VERSION ""

NS_ :

BS_:

BU_: Vector__XXX

// Jaguar XF X250 — MS Bus (125 kbps)
// Confidence prefixes: c_ confirmed, i_ inferred, u_ unknown
// See README.md for sourcing and confidence definitions.
// Do not apply PSA or other-platform DBC labels to these frame IDs.

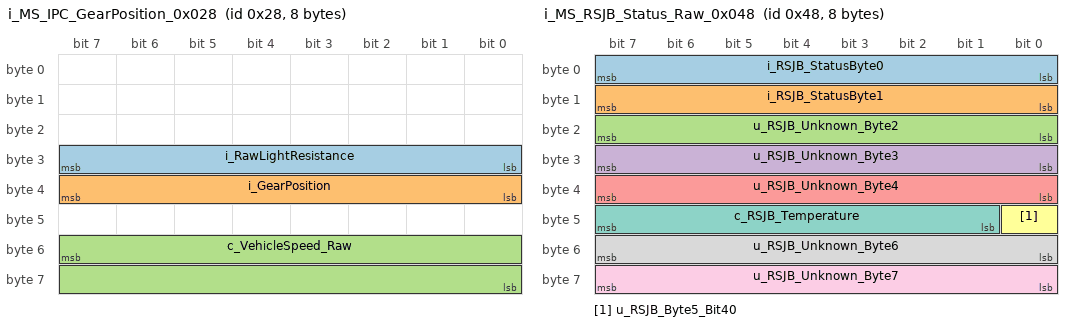
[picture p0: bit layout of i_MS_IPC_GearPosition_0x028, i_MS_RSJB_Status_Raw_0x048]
BO_ 40 i_MS_IPC_GearPosition_0x028: 8 Vector__XXX
 SG_ i_RawLightResistance : 24|8@1+ (1,0) [0|255] "" Vector__XXX
 SG_ i_GearPosition : 32|8@1+ (1,0) [0|255] "" Vector__XXX
 SG_ c_VehicleSpeed_Raw : 55|16@0+ (1,0) [0|65535] "raw" Vector__XXX

BO_ 72 i_MS_RSJB_Status_Raw_0x048: 8 Vector__XXX
 SG_ i_RSJB_StatusByte0 : 0|8@1+ (1,0) [0|255] "" Vector__XXX
 SG_ i_RSJB_StatusByte1 : 8|8@1+ (1,0) [0|255] "" Vector__XXX
 SG_ u_RSJB_Unknown_Byte2 : 16|8@1+ (1,0) [0|255] "" Vector__XXX
 SG_ u_RSJB_Unknown_Byte3 : 24|8@1+ (1,0) [0|255] "" Vector__XXX
 SG_ u_RSJB_Unknown_Byte4 : 32|8@1+ (1,0) [0|255] "" Vector__XXX
 SG_ u_RSJB_Byte5_Bit40 : 40|1@1+ (1,0) [0|1] "" Vector__XXX
 SG_ c_RSJB_Temperature : 41|7@1+ (1,-40) [-40|80] "degC" Vector__XXX
 SG_ u_RSJB_Unknown_Byte6 : 48|8@1+ (1,0) [0|255] "" Vector__XXX
 SG_ u_RSJB_Unknown_Byte7 : 56|8@1+ (1,0) [0|255] "" Vector__XXX

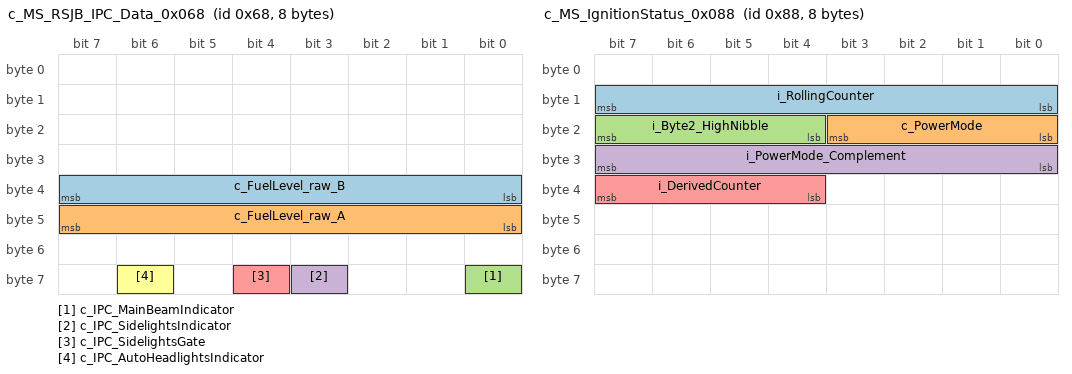
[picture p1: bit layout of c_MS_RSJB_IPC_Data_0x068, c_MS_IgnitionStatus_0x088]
BO_ 104 c_MS_RSJB_IPC_Data_0x068: 8 Vector__XXX
 SG_ c_FuelLevel_raw_B             : 32|8@1+ (1,0) [0|65535] "" Vector__XXX
 SG_ c_FuelLevel_raw_A             : 40|8@1+ (1,0) [0|65535] "" Vector__XXX
 SG_ c_IPC_MainBeamIndicator       : 56|1@1+  (1,0) [0|1] "" Vector__XXX
 SG_ c_IPC_SidelightsIndicator     : 59|1@1+  (1,0) [0|1] "" Vector__XXX
 SG_ c_IPC_SidelightsGate          : 60|1@1+  (1,0) [0|1] "" Vector__XXX
 SG_ c_IPC_AutoHeadlightsIndicator : 62|1@1+ (1,0) [0|1] "" Vector__XXX

BO_ 136 c_MS_IgnitionStatus_0x088: 8 Vector__XXX
 SG_ i_RollingCounter : 8|8@1+ (1,0) [0|255] "" Vector__XXX
 SG_ c_PowerMode : 16|4@1+ (1,0) [0|15] "" Vector__XXX
 SG_ i_Byte2_HighNibble : 20|4@1+ (1,0) [0|15] "" Vector__XXX
 SG_ i_PowerMode_Complement : 24|8@1+ (1,0) [0|255] "" Vector__XXX
 SG_ i_DerivedCounter : 36|4@1+ (1,0) [0|15] "" Vector__XXX

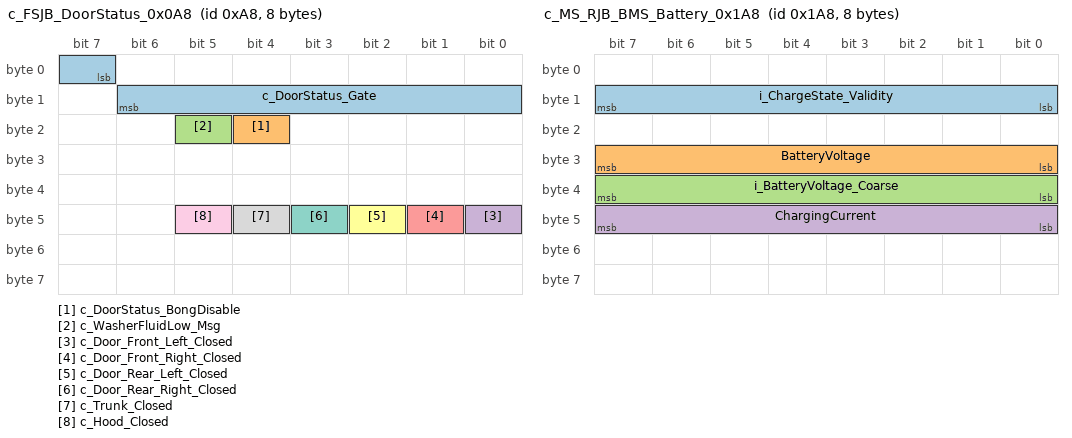
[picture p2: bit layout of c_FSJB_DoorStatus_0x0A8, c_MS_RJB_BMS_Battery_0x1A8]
BO_ 168 c_FSJB_DoorStatus_0x0A8: 8 Vector__XXX
 SG_ c_DoorStatus_Gate           : 7|8@1+ (1,0) [0|1] "" Vector__XXX
 SG_ c_DoorStatus_BongDisable    : 20|1@1+ (1,0) [0|1] "" Vector__XXX
 SG_ c_WasherFluidLow_Msg        : 21|1@1+ (1,0) [0|1] "" Vector__XXX
 SG_ c_Door_Front_Left_Closed    : 40|1@1+ (1,0) [0|1] "" Vector__XXX
 SG_ c_Door_Front_Right_Closed   : 41|1@1+ (1,0) [0|1] "" Vector__XXX
 SG_ c_Door_Rear_Left_Closed     : 42|1@1+ (1,0) [0|1] "" Vector__XXX
 SG_ c_Door_Rear_Right_Closed    : 43|1@1+ (1,0) [0|1] "" Vector__XXX
 SG_ c_Trunk_Closed              : 44|1@1+ (1,0) [0|1] "" Vector__XXX
 SG_ c_Hood_Closed               : 45|1@1+ (1,0) [0|1] "" Vector__XXX

BO_ 200 c_MS_IPC_Unknown_0x0C8: 8 Vector__XXX
BO_ 264 c_MS_IPC_Unknown_0x108: 8 Vector__XXX
 SG_ c_RPM       : 20|13@0+ (1,0) [0|8191] "rpm" Vector__XXX
BO_ 360 c_MS_IPC_TurnIndicatorRequest_0x168: 8 Vector__XXX
 SG_ c_TurnSwitchState : 0|4@1+ (1,0) [0|15] "" Vector__XXX

BO_ 392 c_MS_IPC_Odometer_0x188: 8 Vector__XXX
 SG_ c_Odometer_KM_Raw   : 32|24@1+  (1,0) [0|16777215] "" Vector__XXX
 SG_ i_AliveToggle_b0    : 6|1@1+ (1,0) [0|1] "" Vector__XXX

BO_ 424 c_MS_RJB_BMS_Battery_0x1A8: 8 Vector__XXX
 SG_ i_ChargeState_Validity : 8|8@1+ (1,0) [0|255] "" Vector__XXX
 SG_ BatteryVoltage : 24|8@1+ (0.050000000745,6) [6|18.75] "V" Vector__XXX
 SG_ i_BatteryVoltage_Coarse : 32|8@1+ (0.1658,7.71) [8|50] "V" Vector__XXX
 SG_ ChargingCurrent : 40|8@1+ (1,-127) [-127|128] "A" Vector__XXX

BO_ 456 i_Smart_Key_LateMY_Unknown_0x1C8: 8 Vector__XXX
 SG_ c_IPC_SmartKeyBatteryLow_Gate   : 3|1@1+  (1,0) [0|1] "" Vector__XXX
 SG_ c_IPC_SmartKeyBatteryLow_Msg    : 39|1@1+  (1,0) [0|1] "" Vector__XXX

BO_ 472 c_MS_IPC_ClockCounterMirror_0x1D8: 8 Vector__XXX
 SG_ c_ClockCounter_32 : 39|32@0+ (1,0) [0|4294967295] "count" Vector__XXX
BO_ 488 c_LateMY_Unknown_0x1E8: 8 Vector__XXX

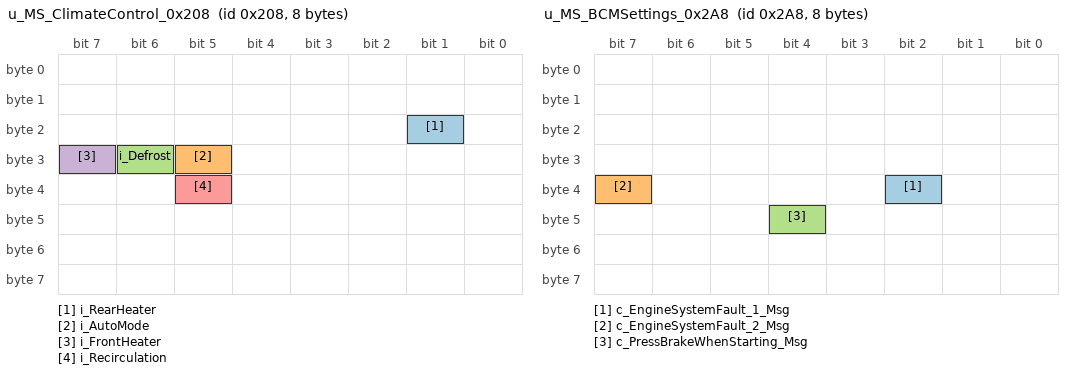
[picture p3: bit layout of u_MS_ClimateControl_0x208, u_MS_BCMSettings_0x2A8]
BO_ 520 u_MS_ClimateControl_0x208: 8 Vector__XXX
 SG_ i_RearHeater : 17|1@1+ (1,0) [0|1] "" Vector__XXX
 SG_ i_AutoMode : 29|1@1+ (1,0) [0|1] "" Vector__XXX
 SG_ i_Defrost : 30|1@1+ (1,0) [0|1] "" Vector__XXX
 SG_ i_FrontHeater : 31|1@1+ (1,0) [0|1] "" Vector__XXX
 SG_ i_Recirculation : 37|1@1+ (1,0) [0|1] "" Vector__XXX

BO_ 552 c_Unknown_Odometer_0x228: 8 Vector__XXX
 SG_ c_Odometer_KM_Raw   : 40|24@1+  (1,0) [0|16777215] "" Vector__XXX

BO_ 616 c_LateMY_Unknown_0x268: 8 Vector__XXX
BO_ 632 c_LateMY_Unknown_0x278: 8 Vector__XXX

BO_ 680 u_MS_BCMSettings_0x2A8: 8 Vector__XXX
 SG_ c_EngineSystemFault_1_Msg : 34|1@1+ (1,0) [0|1] "" Vector__XXX
 SG_ c_EngineSystemFault_2_Msg : 39|1@1+ (1,0) [0|1] "" Vector__XXX
 SG_ c_PressBrakeWhenStarting_Msg : 44|1@1+ (1,0) [0|1] "" Vector__XXX

BO_ 712 c_LateMY_Unknown_0x2C8: 8 Vector__XXX
BO_ 714 c_LateMY_Unknown_0x2CA: 8 Vector__XXX
BO_ 744 c_Unknown_Odometer_0x2E8: 8 Vector__XXX
 SG_ c_Odometer_KM_Raw   : 40|24@1+  (1,0) [0|16777215] "" Vector__XXX

BO_ 776 c_LateMY_Unknown_0x308: 8 Vector__XXX

BO_ 808 c_LateMY_Unknown_0x328: 8 Vector__XXX

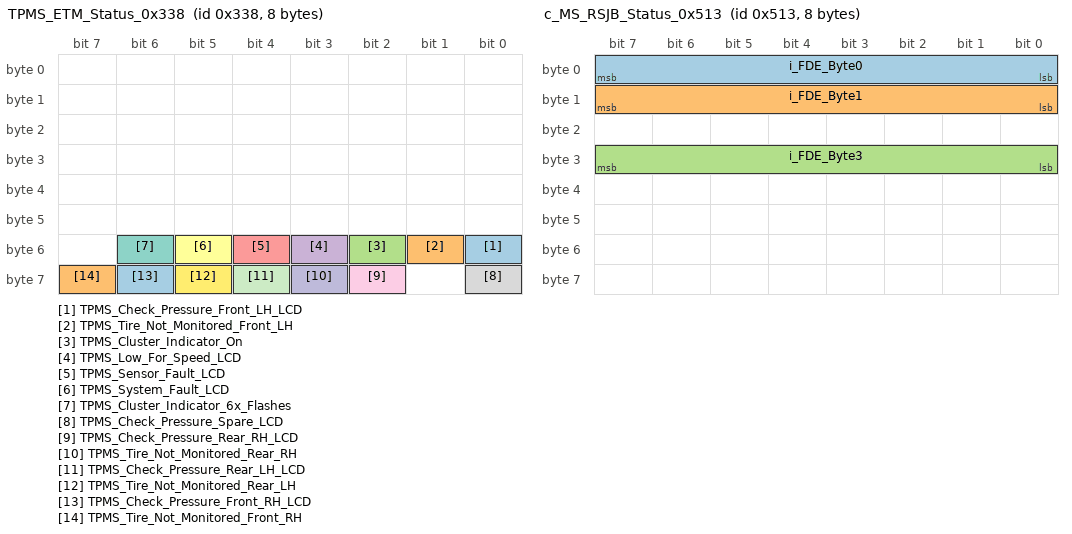
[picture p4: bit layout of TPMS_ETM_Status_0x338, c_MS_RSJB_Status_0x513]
BO_ 824 TPMS_ETM_Status_0x338: 8 Vector__XXX
 SG_ TPMS_Check_Pressure_Front_LH_LCD       : 48|1@1+ (1,0) [0|1] "" Vector__XXX
 SG_ TPMS_Tire_Not_Monitored_Front_LH       : 49|1@1+ (1,0) [0|1] "" Vector__XXX
 SG_ TPMS_Cluster_Indicator_On              : 50|1@1+ (1,0) [0|1] "" Vector__XXX
 SG_ TPMS_Low_For_Speed_LCD                 : 51|1@1+ (1,0) [0|1] "" Vector__XXX
 SG_ TPMS_Sensor_Fault_LCD                  : 52|1@1+ (1,0) [0|1] "" Vector__XXX
 SG_ TPMS_System_Fault_LCD                  : 53|1@1+ (1,0) [0|1] "" Vector__XXX
 SG_ TPMS_Cluster_Indicator_6x_Flashes      : 54|1@1+ (1,0) [0|1] "" Vector__XXX
 SG_ TPMS_Check_Pressure_Spare_LCD          : 56|1@1+ (1,0) [0|1] "" Vector__XXX
 SG_ TPMS_Check_Pressure_Rear_RH_LCD        : 58|1@1+ (1,0) [0|1] "" Vector__XXX
 SG_ TPMS_Tire_Not_Monitored_Rear_RH        : 59|1@1+ (1,0) [0|1] "" Vector__XXX
 SG_ TPMS_Check_Pressure_Rear_LH_LCD        : 60|1@1+ (1,0) [0|1] "" Vector__XXX
 SG_ TPMS_Tire_Not_Monitored_Rear_LH        : 61|1@1+ (1,0) [0|1] "" Vector__XXX
 SG_ TPMS_Check_Pressure_Front_RH_LCD       : 62|1@1+ (1,0) [0|1] "" Vector__XXX
 SG_ TPMS_Tire_Not_Monitored_Front_RH       : 63|1@1+ (1,0) [0|1] "" Vector__XXX

BO_ 840 c_MS_IPC_Unknown_0x348: 8 Vector__XXX
BO_ 848 c_LateMY_Unknown_0x350: 8 Vector__XXX
BO_ 872 c_LateMY_Unknown_0x368: 8 Vector__XXX
BO_ 888 c_MS_IPC_ClockMinSec_0x378: 8 Vector__XXX
 SG_ i_Clock_Minutes : 48|8@1+ (1,0) [0|59] "min" Vector__XXX
 SG_ i_Clock_Seconds : 56|8@1+ (1,0) [0|59] "s" Vector__XXX

BO_ 904 c_MS_IPC_Odometer_0x388: 8 Vector__XXX
 SG_ c_Odometer_KM_Raw   : 40|24@1+  (1,0) [0|16777215] "" Vector__XXX

BO_ 918 u_MS_WarningState_0x396: 8 Vector__XXX
 SG_ u_Warning_Byte7 : 56|8@1+ (1,0) [0|255] "" Vector__XXX

BO_ 919 c_MS_IPC_Unknown_0x397: 8 Vector__XXX
 SG_ i_Warning_Byte7 : 56|8@1+ (1,0) [0|255] "" Vector__XXX

BO_ 952 c_LateMY_Unknown_0x3B8: 8 Vector__XXX
BO_ 956 c_MS_IPC_Unknown_0x3BC: 8 Vector__XXX
BO_ 968 c_MS_IPC_Unknown_0x3C8: 8 Vector__XXX

BO_ 1024 c_MS_CCF_Block1_0x400: 8 Vector__XXX
 SG_ i_CCF_LineNumber : 0|8@1+ (1,0) [0|255] "" Vector__XXX

BO_ 1025 c_MS_CCF_Block2_0x401: 8 Vector__XXX
 SG_ i_CCF_LineNumber : 0|8@1+ (1,0) [0|255] "" Vector__XXX

BO_ 1028 c_MS_FSJB_CCFVehicle_Status_0x404: 8 Vector__XXX
 SG_ Mux_404 M : 0|8@1+ (1,0) [0|255] "" Vector__XXX

 SG_ Status_01_Value_1 m1 : 8|16@1+ (1,0) [0|65535] "" Vector__XXX
 SG_ Status_01_Value_2 m1 : 32|16@1+ (1,0) [0|65535] "" Vector__XXX

 SG_ Vehicle_Battery_Voltage m2 : 32|8@1+ (0.25,0) [0|63.75] "V" Vector__XXX

 SG_ VIN_SEGMENT_10_1 m16 : 8|8@1+ (1,0) [0|255] "" Vector__XXX
 SG_ VIN_SEGMENT_10_2 m16 : 16|8@1+ (1,0) [0|255] "" Vector__XXX
 SG_ VIN_SEGMENT_10_3 m16 : 24|8@1+ (1,0) [0|255] "" Vector__XXX
 SG_ VIN_SEGMENT_10_4 m16 : 32|8@1+ (1,0) [0|255] "" Vector__XXX
 SG_ VIN_SEGMENT_10_5 m16 : 40|8@1+ (1,0) [0|255] "" Vector__XXX
 SG_ VIN_SEGMENT_10_6 m16 : 48|8@1+ (1,0) [0|255] "" Vector__XXX
 SG_ VIN_SEGMENT_10_7 m16 : 56|8@1+ (1,0) [0|255] "" Vector__XXX

 SG_ VIN_SEGMENT_11_1 m17 : 8|8@1+ (1,0) [0|255] "" Vector__XXX
 SG_ VIN_SEGMENT_11_2 m17 : 16|8@1+ (1,0) [0|255] "" Vector__XXX
 SG_ VIN_SEGMENT_11_3 m17 : 24|8@1+ (1,0) [0|255] "" Vector__XXX
 SG_ VIN_SEGMENT_11_4 m17 : 32|8@1+ (1,0) [0|255] "" Vector__XXX
 SG_ VIN_SEGMENT_11_5 m17 : 40|8@1+ (1,0) [0|255] "" Vector__XXX
 SG_ VIN_SEGMENT_11_6 m17 : 48|8@1+ (1,0) [0|255] "" Vector__XXX
 SG_ VIN_SEGMENT_11_7 m17 : 56|8@1+ (1,0) [0|255] "" Vector__XXX

 SG_ VIN_SEGMENT_12_1 m18 : 8|8@1+ (1,0) [0|255] "" Vector__XXX
 SG_ VIN_SEGMENT_12_2 m18 : 16|8@1+ (1,0) [0|255] "" Vector__XXX
 SG_ VIN_SEGMENT_12_3 m18 : 24|8@1+ (1,0) [0|255] "" Vector__XXX

BO_ 1029 c_MS_FSJB_CCFVehicle_Status_0x405: 8 Vector__XXX
 SG_ Mux_405 M : 0|8@1+ (1,0) [0|255] "" Vector__XXX

 SG_ Status_01_Value_1 m1 : 8|16@1+ (1,0) [0|65535] "" Vector__XXX
 SG_ Status_01_Value_2 m1 : 32|16@1+ (1,0) [0|65535] "" Vector__XXX

 SG_ Vehicle_Battery_Voltage m2 : 32|8@1+ (0.25,0) [0|63.75] "V" Vector__XXX

 SG_ VIN_SEGMENT_10_1 m16 : 8|8@1+ (1,0) [0|255] "" Vector__XXX
 SG_ VIN_SEGMENT_10_2 m16 : 16|8@1+ (1,0) [0|255] "" Vector__XXX
 SG_ VIN_SEGMENT_10_3 m16 : 24|8@1+ (1,0) [0|255] "" Vector__XXX
 SG_ VIN_SEGMENT_10_4 m16 : 32|8@1+ (1,0) [0|255] "" Vector__XXX
 SG_ VIN_SEGMENT_10_5 m16 : 40|8@1+ (1,0) [0|255] "" Vector__XXX
 SG_ VIN_SEGMENT_10_6 m16 : 48|8@1+ (1,0) [0|255] "" Vector__XXX
 SG_ VIN_SEGMENT_10_7 m16 : 56|8@1+ (1,0) [0|255] "" Vector__XXX

 SG_ VIN_SEGMENT_11_1 m17 : 8|8@1+ (1,0) [0|255] "" Vector__XXX
 SG_ VIN_SEGMENT_11_2 m17 : 16|8@1+ (1,0) [0|255] "" Vector__XXX
 SG_ VIN_SEGMENT_11_3 m17 : 24|8@1+ (1,0) [0|255] "" Vector__XXX
 SG_ VIN_SEGMENT_11_4 m17 : 32|8@1+ (1,0) [0|255] "" Vector__XXX
 SG_ VIN_SEGMENT_11_5 m17 : 40|8@1+ (1,0) [0|255] "" Vector__XXX
 SG_ VIN_SEGMENT_11_6 m17 : 48|8@1+ (1,0) [0|255] "" Vector__XXX
 SG_ VIN_SEGMENT_11_7 m17 : 56|8@1+ (1,0) [0|255] "" Vector__XXX

 SG_ VIN_SEGMENT_12_1 m18 : 8|8@1+ (1,0) [0|255] "" Vector__XXX
 SG_ VIN_SEGMENT_12_2 m18 : 16|8@1+ (1,0) [0|255] "" Vector__XXX
 SG_ VIN_SEGMENT_12_3 m18 : 24|8@1+ (1,0) [0|255] "" Vector__XXX

BO_ 1096 c_MS_CCF_ITP_0x448: 8 Vector__XXX
BO_ 1160 c_LateMY_Unknown_0x488: 8 Vector__XXX
BO_ 1161 c_LateMY_Unknown_0x489: 8 Vector__XXX
BO_ 1162 c_LateMY_Unknown_0x48A: 8 Vector__XXX
BO_ 1167 c_LateMY_Unknown_0x48F: 8 Vector__XXX
BO_ 1183 c_LateMY_Unknown_0x49F: 8 Vector__XXX

BO_ 1200 c_LateMY_Unknown_0x4B0: 8 Vector__XXX
BO_ 1226 c_MS_IPC_Unknown_0x4CA: 8 Vector__XXX
BO_ 1257 c_MS_IPC_ClockMinSec_0x4E9: 8 Vector__XXX
 SG_ i_Clock_Minutes : 48|8@1+ (1,0) [0|59] "min" Vector__XXX
 SG_ i_Clock_Seconds : 56|8@1+ (1,0) [0|59] "s" Vector__XXX
BO_ 1264 c_MS_IPC_Unknown_0x4F0: 8 Vector__XXX
BO_ 1276 c_LateMY_Unknown_0x4FC: 8 Vector__XXX

BO_ 296 c_MS_IPC_MemorySettingsMessages_0x128: 8 Vector__XXX
 SG_ c_Memory1Recalled : 51|1@1+ (1,0) [0|1] "" Vector__XXX
 SG_ c_Memory2Recalled : 52|1@1+ (1,0) [0|1] "" Vector__XXX
 SG_ c_Memory3Recalled : 51|2@1+ (1,0) [0|3] "" Vector__XXX
 SG_ c_Memory1Saved : 59|1@1+ (1,0) [0|1] "" Vector__XXX
 SG_ c_Memory2Saved : 60|1@1+ (1,0) [0|1] "" Vector__XXX
 SG_ c_Memory3Saved : 59|2@1+ (1,0) [0|3] "" Vector__XXX

BO_ 1281 c_MS_IPC_Unknown_0x501: 8 Vector__XXX
BO_ 1282 c_MS_HDM_Status_0x502: 8 Vector__XXX
BO_ 1283 c_MS_RCC_Status_0x503: 8 Vector__XXX
BO_ 1284 c_MS_DDCU_Status_0x504: 8 Vector__XXX
BO_ 1285 c_MS_PDCU_Status_0x505: 8 Vector__XXX
BO_ 1288 c_MS_KVM_Status_0x508: 8 Vector__XXX
BO_ 1291 c_MS_DSM_Status_0x50B: 8 Vector__XXX
BO_ 1292 c_MS_ICM_Status_0x50C: 8 Vector__XXX
BO_ 1295 c_MS_ICP_Status_0x50F: 8 Vector__XXX
BO_ 1297 c_MS_FSJB_Status_0x511: 8 Vector__XXX
BO_ 1299 c_MS_RSJB_Status_0x513: 8 Vector__XXX
 SG_ i_FDE_Byte0 : 0|8@1+ (1,0) [0|255] "" Vector__XXX
 SG_ i_FDE_Byte1 : 8|8@1+ (1,0) [0|255] "" Vector__XXX
 SG_ i_FDE_Byte3 : 24|8@1+ (1,0) [0|255] "" Vector__XXX

BO_ 1310 c_LateMY_Unknown_0x51E: 8 Vector__XXX
BO_ 1320 c_MS_PSM_Status_0x528: 8 Vector__XXX
BO_ 1371 c_LateMY_Unknown_0x55B: 8 Vector__XXX

CM_ BO_ 40 "i_GearSelector: Source Rhys Morgan Id40.js.
Byte 4 bitmask: P=0x00 R=0x01 N=0x02 D=0x04 S=0x08.
BENCH-CONFIRMED 2026-08-16 (search_speed_mirror_ms.py): bytes 6-7 (16-bit BE) = VEHICLE SPEED, a 1:1 mirror of the HS 0x20B raw value (the cluster re-broadcasts the speed it consumes). c_VehicleSpeed_Raw is the RAW; the raw->mph DISPLAY is CCF-biased (GROUP_CCF_EUCD_SPEEDO_BIAS grp113 / JAG_SPEEDO_PERCENTAGE_SCALE grp174=2.0% / WHEEL_DIMENSION_RIM_DIAMETER grp186, via 0x400/0x401), not a fixed constant. For THIS bench's CCF, display_mph = 0.006360*raw - 0.30 was bench-validated (30->30, 100->100 confirmed by eye) -- CCF/wheel-specific, re-fit for a different CCF.";

CM_ BO_ 72 "c_MS_RSJB_Status_Raw_0x048: Provisional reverse engineering. Frame observed from multiple vehicles. Appears to originate from RSJB (Rear Junction Box). FUEL LABEL REMOVED 2026-08-16: byte4/byte5 were previously guessed as raw fuel sender values -- bench re-validation via ETM test mode confirms the cluster's FUEL INPUT is 0x068, NOT 0x048 (driving values here has no effect). Byte4 is u_ (unknown). BYTE5 TEMPERATURE CONFIRMED (bench 2026-08-19): bits 41-47 carry a temperature signal, range -40..+80C, encoded factor 1.0 / offset -40 (equivalently byte5 x0.5 -40 when bit40=0; matches L322 log replay -38C/-1C). Bit40 is not part of the temperature (u_). The old fuel correspondence note is retained below only as historical rationale, now superseded. Byte0/Byte1 are currently unknown status fields. Observation across two vehicles: Byte0 value FE dominates (~80% of frames) while FF occurs ~20% of frames. When Byte0=FF, Byte1 is typically 0x80; when Byte0=FE, Byte1 is typically 0x00. Pattern is periodic and independent of fuel sender changes, suggesting an alive indicator, rolling status bit, sample-valid marker, or message state field. Do not assume FE/FF represents fuel data. Byte2/Byte3/Byte6/Byte7 remain unidentified. Source: multi-vehicle candump analysis.";

CM_ BO_ 104 "c_FuelLevel: Bench confirmed (Rhys Morgan can-utils candump + multi-fill bench test). ~50ms interval. Bytes 3-4 = LE uint16 fuel level raw. CALIBRATION TABLE (raw -> %): 5259=33%, 13370=50%, 25657=66%, 28220=75%, 35604=80%. Non-linear -- piecewise interpolation required, not a simple scale factor. Bytes 5-6 static (0xD0, 0x42) -- confirmed NOT part of the fuel value. Pairs with 0x513 for needle movement (40s averaging delay).

Byte 7 also carries multiple IPC indicator status bits:
- b7.0 = Main beam indicator.
- b7.3 = Sidelights indicator.
- b7.4 = Gates b7.3 when asserted; likely represents the automatic lighting mode/state that enables the sidelights indicator.
- b7.6 = Headlights auto indicator.

Source: candump-2026-07-16_213719.log + candump-2019-11-01_185625.log + candumpStartup.log + bench test.

NEW CROSS-DEPENDENCY (in progress): replaying candump-2020-04-24_130328.log on MS alongside this project's own 0x068 (this frame is NOT present in that log dump) set 5 modules to CONNECTED. Removing 0x068 from the mix while still replaying the log dropped those same 5 modules back to MISSING -- confirms 0x068 is NECESSARY for this effect, but not yet known if it's SUFFICIENT alone, since the log dump's other frames were present throughout. Which 5 modules, and which specific companion frame(s) from the log are actually required alongside 0x068, are both still being isolated -- do not assume 0x068 alone explains this yet.

All MS bus ETM module-status frames confirmed so far appear to be gated by this frame (0x068). Working theory: 0x068 may function as a general vehicle data valid / bus fully awake precondition the cluster checks before evaluating ANY MS bus module status, rather than a fuel-specific signal -- consistent with RSJB (the module that actually owns fuel reporting, see 0x513) needing to be considered live before other modules are checked. Treat 0x068 as a baseline requirement alongside minimalKeepAlive.js for any module-status testing going forward.";

CM_ BO_ 136 "c_MS_IgnitionStatus_0x088: cluster wake / ignition keepalive from the CJB, ~20ms. CONFIRMED MS-only — sending on HS alone does NOT wake the cluster. Wake is gated by c_PowerMode (byte2 0-based, low nibble = JLR Power Mode): bench-confirmed modes 6/7/9 wake (IGN=CONNECTED), mode 4 (Accessory) gives LCD backlight only, mode 0 is off. (Earlier ''byte 3 = 0x06'' used 1-based counting = byte index 2; the previous c_IgnitionOn_b3 signal at bit24/byte3 was mislocated on the complement byte — corrected to c_PowerMode at bit16.) i_RollingCounter (byte1), i_PowerMode_Complement (byte3 = 0x10|(0x0F-(byte2&0x0F))) and i_DerivedCounter (byte4) match genuine candump traffic but are NOT required to wake. Side effect: while 0x088 is sent PIE reads FAULTY in ETM; stopping it moves PIE/PATS/TPMS to WAITING (module polling halts) — a power-state effect, not a fix. See xf250-can-re/frames/0136_0x088_MS.md.";

CM_ BO_ 456 "i_Smart_Key_LateMY_Unknown_0x1C8: CONFIRMED by bench test -- drives ICP LCD messages for Smart Key Battery Low. Confirmed from candump-2026-07-16_213719.log on a late MY XF250
  Smary Key Battery Low: byte4 = mask 0x80. Gated by byte0 = mask 0x08";

CM_ BO_ 918 "u_WarningState_0x396: TX frame (not cluster-owned, corrected from an earlier guess). Direct bench test: RULED OUT for the tire pressure warning specifically -- no effect. Absent from the 52s clean dump (candump-2020-04-24_130142.log) regardless. Actual TPMS trigger is 0x401 (JLR CCF, see that message''s comment). Purpose of 0x396 itself remains unknown -- may relate to one of the other three warnings (front indicator/rear taillamp/blind spot) not yet individually tested.";
CM_ BO_ 919 "c_MS_ICP_Unknown_0x397: CONFIRMED cluster-owned (already observed as Rx from the cluster, per user) -- DO NOT TRANSMIT, same category as 0x457 (risk of bus ID collision). Cross-checked against the clean dump (candump-2020-04-24_130142.log): also absent there, consistent with being the cluster''s own fault-state output that only appears when the fault is active. Read as a symptom, not a cause.";

CM_ BO_ 1024 "i_CCF_Block1_0x400: Part of the JLR Car Configuration File (CCF) broadcast -- Block One, EUCD platform. byte0 = line number within the CCF (the frame cycles through sequential lines, not a single static payload -- matches the multi-step transition pattern observed in candump analysis). Not yet independently probed for effects -- 0x401 (Block Two) is where the confirmed TPMS effect and VIN data live, see that message''s comment.";
CM_ BO_ 1025 "c_CCF_Block2_0x401: Part of the JLR Car Configuration File (CCF) broadcast -- Block Two, T5 platform. byte0 = line number within the CCF. 
  Lines 01/02/03 contain the VIN (line 01 starts with vehicle type e.g. L359, brand e.g. Land Rover, model year e.g. 14). 
  CONFIRMED by direct bench test: this frame creates and clears warnings by setting the system with fault to disabled
  MAJOR FINDING: modifying CCF content and feeding it to the FCDIM (display/MMI module) changes which vehicle software identity it loads -- e.g. switching between Range Rover and Jaguar configurations.
  This is a shared JLR display platform mechanism, not XF250-specific -- worth treating CCF content with real care given it can reconfigure what the display module believes it is. 
  NEXT STEP: isolate which specific CCF line/byte controls the TPMS warning specifically, rather than replaying the whole block. 

  Blind Spot Monitor Not Available: byte0 = 0x1C, byte3 = mask 0x80  (Group 36 mask 0x01) (Group 191 mask 0x80)
  Tire Pressure System Fault:  byte0 = 0x1C, byte3 = mask 0x02 (Group 100 mask 0x01) (Group 36 mask 0x03 - No TPMS )
  Steering Column Lock: byte0 = 0x08, byte2 = mask 0x04   (Group 50 mask 0x04)
  Brake Pads Low: byte0 = 0x17, byte 6 = mask 0x40 value 0x00 (Group 159 mask 0x40)
  Check Pedestrian System: byte0 = 0x17, byte 6 = mask 0x80  (Group 159 mask 0x80)
  EPB Disable: byte0 = 0x06, byte 6 (Group 40 mask 0x10 0x401 - Doesn't clear fault) (Group 104 set 0x01 0x400 0F byte 7 0x01 - Doesn't clear fault)
  Battery Monitor Sensor (Group 210, value 0x01 0x400 : 0x1F, byte 1 - Doesn't clear fault)
  Low Coolant (Group 170, value 0x00 mask 0x02 0x401 : 0x1A byte 3)

  Seatbelt reminder 401:0x1A, byte 1 changed from 0x7F to 0x7C to disable seatbelt reminder and audible sound
  mux  = (offset / 7) + 1        // integer division
  byte = (offset % 7) + 1
  These are the specific line/byte within the CCF broadcast responsible for the TPMS and BSM warnings (see hs_bus.dbc for the per-line trigger/clear payload table already extracted from candumpStartup.log vs candump-2020-04-24_130142.log for this same line). Resolves the earlier open question of exactly which CCF line controls these warnings. IMPORTANT NUANCE (ETM): even with this frame''s TPMS-fault bit cleared and the warning icon suppressed, ETM Module Status test still shows TPMS as FAULTY -- confirms warning-suppression and module-presence are SEPARATE mechanisms. This frame only handles the icon; making TPMS itself show CONNECTED would need a genuine TPMS module status frame, not yet found (separate open problem, not solved by the CCF fix).";
CM_ BO_ 1029 "JLR Vehicle Status 0x405 multiplexed message. Mux 0x02 carries battery voltage at byte 4, scale 0.25V. Mux 0x10/0x11/0x12 carry VIN ASCII segments.";
CM_ BO_ 1028 "JLR Vehicle Status 0x404 multiplexed message. Mux 0x02 carries battery voltage at byte 4, scale 0.25V. Mux 0x10/0x11/0x12 carry VIN ASCII segments.";

CM_ BO_ 1283 "c_RCC_Status_0x503: CONFIRMED by bench test -- drives RCC (Rear Climate Control) module status in ETM. Same FAULTY -> CONNECTED -> MISSING pattern seen across all module-status frames on this project. NOTE: 0x504/0x505 exist as SEPARATE, DIFFERENT frames on the HS bus (see hs_bus.dbc, ruled out for TPMS) -- CAN IDs are only unique per-bus, no conflict, just don''t confuse the two.";
CM_ BO_ 1284 "c_DDCU_Status_0x504: CONFIRMED by bench test -- drives DDCU (Driver Door Control Unit) module status. Same pattern as other module-status frames. HISTORY: this ID was previously investigated as a TPMS candidate (comparing faulty vs clean MS candumps, a byte3 0x01-vs-0x03 difference was found but later confirmed CORRELATIONAL not causal -- ruled out for TPMS, the real TPMS trigger is 0x401/CCF). Confirmed now-superseding purpose: DDCU module status.";
CM_ BO_ 1285 "c_PDCU_Status_0x505: CONFIRMED by bench test -- drives PDCU (Passenger Door Control Unit) module status. Same pattern as other module-status frames. HISTORY: same TPMS-candidate investigation as 0x504 (see that comment) -- ruled out for TPMS, confirmed now-superseding purpose: PDCU module status.";
CM_ BO_ 1288 "c_KVM_Status_0x508: CONFIRMED by bench test -- drives KVM (Keyless Vehicle Module) status. Same pattern as other module-status frames.";
CM_ BO_ 1291 "c_DSM_Status_0x50B: CONFIRMED by bench test -- drives DSM (Driver Seat Module) status. Same pattern as other module-status frames.";
CM_ BO_ 1292 "c_ICM_Status_0x50C: CONFIRMED by bench test -- drives ICM (Infotainment Control Module) status. Same pattern as other module-status frames.";
CM_ BO_ 1295 "c_ICP_Status_0x50F: CONFIRMED by bench test -- drives ICP (Integrated Control Panel) status. Same pattern as other module-status frames.";
CM_ BO_ 1297 "c_ClusterOwned_Backlighting_0x511: CONFIRMED cluster-owned on MS bus -- DO NOT TRANSMIT. Initially misidentified as a cluster backlighting frame safe to send; user corrected this after further testing -- treat the same as 0x397/0x457/0x337 (risk of bus ID collision). NOTE: 0x511 also exists as a SEPARATE, different HS-bus frame (see hs_bus.dbc, i_HSInitState_0x511, init state machine, also cluster-owned/not for TX) -- CAN IDs are only unique per-bus, these are two distinct frames that happen to share a number, both cluster-owned on their respective buses.";
CM_ BO_ 1299 "i_FuelDisplayEnable: Required for cluster to drive the fuel gauge needle -- without this frame the cluster ignores 0x068 fuel data. 40s averaging delay after first seen. SETTLED payload (both Rhys candumps): 01 02 00 0C 13 00 00 01. STARTUP payload also observed: 13 01 00 00 13 00 00 03 (init state, before settling). Transmit at ~50ms. Still i_ -- not yet independently bench-confirmed on this project''s hardware. Source: candump-2019-11-01_185625.log + candumpStartup.log. ETM BUG FOUND: Rolling Counts test shows FUEL as ''---'' (invalid/not received) while ODO shows a real value -- confirms the fuel rolling counter is not being satisfied. Current ms.js payloads for this frame are fully static (copied verbatim from single captured frames), with no incrementing counter anywhere -- very likely the actual gap. ALSO: ETM fuel RAW shows as two separate 8-bit values (255, 255 observed = both invalid/open-circuit per the official diagnostic chart), not a single 16-bit value -- this contradicts the byte3-4 LE uint16 model used for 0x068 and suggests RAW A/B may be two independent 8-bit channels instead. The 99.6% shown on the LCD during this same test is more likely coming from 0x07E''s simple byte4 mechanism (already running throughout this project) than from 0x068/0x513 at all -- the calibrated 0x068 work is unverified as actually feeding anything the cluster trusts yet. UPDATE: RAW subsequently observed as 235, 255 (was 255, 255) -- one channel now reads a plausible in-range value (10-254 = normal per the official diagnostic chart), the other still invalid. Cause of the change not yet identified -- worth retesting deliberately rather than assuming causation from other changes made in between. MAJOR UPDATE: enabling 0x4D5 (ECM status, see hs_bus.dbc) enabled the fuel rolling count in ETM -- this may fully explain the earlier invalid/---/broken rolling count without 0x513 needing an internal incrementing counter of its own. The static payloads here may be sufficient once 0x4D5 is part of the standard baseline -- worth retesting this frame in isolation now that 0x4D5 exists, before assuming a counter needs to be added here. CONFIRMED (separately) to drive RSJB (Rear Smart Junction Box) module status in ETM -- same FAULTY -> CONNECTED -> MISSING pattern. This likely explains the original fuel-display-enable finding: RSJB is the module that actually reads/reports fuel sensor data in this architecture, so its presence being confirmed is plausibly WHY fuel needle movement depends on this frame, rather than this frame being a fuel-specific enable in its own right.";

CM_ BO_ 264 "c_MS_IPC_Unknown_0x108: BENCH-CONFIRMED 2026-08-16 (validate_rpm_mirror_0x108.py). Bytes 2-3 (13-bit BE, mask ~0xE000) = ENGINE RPM, a 1:1 mirror of the HS 0x295 ECM RPM the cluster consumes (injected 800/1500/3000/5000 rpm -> read back identically). Scale is 1:1 (raw = rpm, no scale/offset). Demonstrates the HS-input -> MS-output RPM relay path.";

CM_ BO_ 424 "c_MS_RJB_BMS_Battery_0x1A8: RJB->cluster MS-CAN message carrying Battery Monitor System (BMS) data. Source per X250 Body Electrical workshop manual (Battery Monitor System.pdf): BMS (in the negative battery cable) measures V+I and computes SOC+SOH, sends to the RJB over LIN, RJB relays on MS-CAN. The cluster is the MS<->HS gateway and forwards battery condition to the ECM on HS (BENCH-CONFIRMED 2026-08-16, validate_battery_relay_hs.py: byte3 voltage -> HS 0x257 byte1; byte5 current -> HS 0x217 byte4, both 1:1). Byte structure (candump + bench): no rolling counter (static per-frame). byte1 = charge-state/validity (0x11 idle: b5=0, b4 parked 0x0E; 0x25/0x2D charging: b5=live current, b4=live). byte3 = battery voltage (fine, 0.05 V/bit). byte4 = coarse voltage (~0.166 V/bit, b4~=0.30*b3-10.3, corr 0.91 in charging state; tracks voltage not current) -- candidate CHARGING/generator voltage vs b3 battery voltage (manual distinguishes them; system defaults to a fixed 13.7 V charging voltage on BMS comms loss). byte5 = charging current (A = b5-127). Expect SOC/SOH too -- they vary slowly, candidates for the per-session-stable bytes b2/b6/b7. NOTE: 'Battery Not Charging' LCD indicates GENERATOR OR BMS faults; sweeping this frame's voltage 11-15V did NOT clear it on an IPC-only bench because the generator side comes from the ECM over HS CAN (absent on the bench). Confirmed present in candump-2026-07-16_213719.log (late MY XF250).";

CM_ BO_ 488 "Confirmed from candump-2026-07-16_213719.log on a late MY XF250";
CM_ BO_ 552 "Confirmed from candump-2026-07-16_213719.log on a late MY XF250";
CM_ BO_ 616 "Confirmed from candump-2026-07-16_213719.log on a late MY XF250";
CM_ BO_ 632 "Confirmed from candump-2026-07-16_213719.log on a late MY XF250";
CM_ BO_ 712 "Confirmed from candump-2026-07-16_213719.log on a late MY XF250";
CM_ BO_ 714 "Confirmed from candump-2026-07-16_213719.log on a late MY XF250";
CM_ BO_ 744 "Confirmed from candump-2026-07-16_213719.log on a late MY XF250";
CM_ BO_ 776 "Confirmed from candump-2026-07-16_213719.log on a late MY XF250";
CM_ BO_ 808 "Confirmed from candump-2026-07-16_213719.log on a late MY XF250";
CM_ BO_ 848 "Confirmed from candump-2026-07-16_213719.log on a late MY XF250";
CM_ BO_ 872 "Confirmed from candump-2026-07-16_213719.log on a late MY XF250";
CM_ BO_ 952 "Confirmed from candump-2026-07-16_213719.log on a late MY XF250";
CM_ BO_ 1096 "Confirmed from candump-2026-07-16_213719.log on a late MY XF250";
CM_ BO_ 1160 "Confirmed from candump-2026-07-16_213719.log on a late MY XF250";
CM_ BO_ 1161 "Confirmed from candump-2026-07-16_213719.log on a late MY XF250";
CM_ BO_ 1162 "Confirmed from candump-2026-07-16_213719.log on a late MY XF250";
CM_ BO_ 1167 "Confirmed from candump-2026-07-16_213719.log on a late MY XF250";
CM_ BO_ 1183 "Confirmed from candump-2026-07-16_213719.log on a late MY XF250";
CM_ BO_ 1200 "Confirmed from candump-2026-07-16_213719.log on a late MY XF250";
CM_ BO_ 1276 "Confirmed from candump-2026-07-16_213719.log on a late MY XF250";
CM_ BO_ 1310 "Confirmed from candump-2026-07-16_213719.log on a late MY XF250";
CM_ BO_ 1371 "Confirmed from candump-2026-07-16_213719.log on a late MY XF250";
CM_ BO_ 168 "c_FSJB_DoorStatus_0x0A8: door/bonnet/trunk status INPUT the cluster consumes (from FSJB). Present in candump-2026-07-16_213719.log (late MY XF250). BENCH-CONFIRMED 2026-08-16 (validate_door_causation.py): driving this frame with byte5=0x3F then 0x3E made the cluster's HS output 0x337 byte2 follow (0x3F -> 0x3E), proving byte5 is the door mask and bit0 = Front-Left. Minimal accepted payload: byte0=0x80 (validity gate), byte2=0x10 (bong disable), byte5=door mask (bit0 FL, 0x3F=all closed).";
CM_ BO_ 472 "c_MS_IPC_ClockCounterMirror_0x1D8: BENCH-CONFIRMED 2026-08-16 (validate_clock_counter.py). Bytes 4-7 are a 32-bit big-endian counter; pre-wake FF FF FF FF. It is the SAME counter, in lock-step, as HS 0x4FF (c_HS_IPC_RTCTimestamp) -- both started at 0x5C0BEDC4 and incremented together. Rate ~10 Hz (increment every ~100ms), measured 9.99/s here vs 10.01/s on 0x4FF -- NOT a 1 Hz seconds clock. The magnitude on the bench (0x5C0B..) resembles a Dec-2018 unix value, but the 2015MF candump-2026-07-16_213719.log has a DIFFERENT cluster reading 0x9C844D74 (~year 2053 if read as epoch) at the same 9.99/s rate -- so the date-resemblance is coincidental and it is definitively NOT unix seconds; it is a free-running counter. CROSS-REVISION VALIDATED on the 2015MF cluster (same s/w family, next revision): 0x1D8 bytes 4-7 = 32-bit BE counter at 9.99/s there too. byte0 bit6 (0x40) toggles per frame like 0x188. Cluster-owned output. SPEED HYPOTHESIS REJECTED 2026-08-16 (search_speed_mirror_ms.py): the 2007MY Rhys decode read bytes 1-2 as speed*0.0065; injecting HS 0x20B speed (needle+LCD tracked correctly) left 0x1D8 bytes 1-2 fixed at 0x0000 -- speed is mirrored on 0x028 b6-7 instead, not here.";
CM_ BO_ 392 "c_MS_IPC_Odometer_0x188: BENCH-CONFIRMED 2026-08-16 (validate_odometer_frames.py). Bytes 4-6 (24-bit LE) = odometer raw; observed 0xD74C0A, identical to 0x388 bytes 5-7 in the same run (the two odometer frames cross-agree). byte0 bit6 (0x40) alternates every frame (i_AliveToggle_b0) -- confirmed as a per-frame toggle; whether it is alive/parity vs an odometer-update strobe is i_ (odometer was static so no update event to correlate).";
CM_ BO_ 904 "c_MS_IPC_Odometer_0x388: BENCH-CONFIRMED 2026-08-16 (validate_odometer_frames.py). Bytes 5-7 (24-bit LE) = odometer raw; observed 0xD74C0A, identical to 0x188 bytes 4-6 -- the two odometer frames cross-agree.";
CM_ BO_ 888 "c_MS_IPC_ClockMinSec_0x378: cluster time output. bytes 6-7 = MM:SS -- byte7 = seconds (ticks +1/sec, wraps at 60), byte6 = minutes (increments when seconds wrap). i_: byte7 as a ~1Hz counter is bench-observed (MY2014 IPC-only PowerOn capture, byte7 0->4 with byte6=0 fresh); the MM:SS wall-clock meaning is corroborated by the 2015MF candump-2026-07-16_213719.log (byte6:byte7 = 43:55 climbing, byte7 wraps 0x3b->00 lifting byte6). Same MM:SS value appears in 0x4E9 in lock-step. NOT synced to real wall time in either capture (free-running RTC) -- the RTC is set by a separate sporadic ICP 'Set time' event frame, not seen in cyclic dumps.";
CM_ BO_ 1257 "c_MS_IPC_ClockMinSec_0x4E9: cluster time output carrying the SAME MM:SS as 0x378 (bytes 6-7, byte7=seconds wraps at 60, byte6=minutes), plus byte0=0x80, byte1 fixed. Same evidence/caveats as 0x378. i_.";

CM_ BO_ 360 "c_MS_IPC_TurnIndicatorRequest_0x168: IPC-TRANSMITTED (TX by the cluster on MS). Turn-indicator REQUEST sent to the CJB, derived from the analog Direction-Indicator resistor-ladder switch on cluster pin C2LF27/1 (with SW_RET return). byte0 = decoded DI switch state; it changes across 0x08-0x0C as the DI-line resistance changes. BENCH-CONFIRMED: ~1kR = OFF (0x08), ~220R = LEFT (0x0A), open-circuit = 0x0B. RIGHT (470R) and short states not yet captured but expected within the 0x08-0x0C range. Bytes 1-7 static in captures (example: 08 00 00 FF FF 00 7B FF). Firmware: DI decode is threshold descriptor sid 0x04 (ADC thresholds 328/616/728/868 -> 5 states short/LEFT/OFF/RIGHT/open); an unwired stalk floats to the open band, which also sets DTC 9D3615 'Turn indicator open circuit'. NOTE: this is the cluster's turn-switch READING output; the green turn TELLTALES themselves are flashed by RJB/RSJB ON/OFF timing (0x048/0x068), and hazards are commanded by the CJB (both arrows).";
CM_ SG_ 360 c_TurnSwitchState "byte0 decoded Direction-Indicator switch state. Confirmed: 0x08=OFF(~1kR), 0x0A=LEFT(~220R), 0x0B=open. Full observed range 0x08-0x0C; RIGHT(470R)/short unconfirmed.";

VAL_ 136 c_PowerMode 0 "IgnitionOff" 4 "Accessory" 6 "IgnitionOn" 7 "EngineRunning" 9 "EngineCranking" ;
VAL_ 360 c_TurnSwitchState 8 "OFF_Neutral" 10 "LEFT" 11 "OpenCircuit_Fault" ;

CM_ BO_ 296 "c_MS_IPC_MemorySettingsMessages_0x128: Seat/steering-column/mirror memory settings LCD messages. BENCH-CONFIRMED 2026-08-16: bit 51 = 'Memory 1 Settings Recalled', bit 52 = 'Memory 2 Settings Recalled', both bits 51+52 = 'Memory 3 Settings Recalled'. Bit 59 = 'Memory 1 Settings Saved' + bong, bit 60 = 'Memory 2 Settings Saved' + bong, both bits 59+60 = 'Memory 3 Settings Saved' + bong. Frame is stateless message-trigger: no counter/checksum. Frequency u_.";
CM_ SG_ 296 c_Memory1Recalled "Bit 51. LCD message: 'Memory 1 Settings Recalled'.";
CM_ SG_ 296 c_Memory2Recalled "Bit 52. LCD message: 'Memory 2 Settings Recalled'.";
CM_ SG_ 296 c_Memory3Recalled "Bits 51+52 combined. LCD message: 'Memory 3 Settings Recalled'.";
CM_ SG_ 296 c_Memory1Saved "Bit 59. LCD message: 'Memory 1 Settings Saved' + audible bong.";
CM_ SG_ 296 c_Memory2Saved "Bit 60. LCD message: 'Memory 2 Settings Saved' + audible bong.";
CM_ SG_ 296 c_Memory3Saved "Bits 59+60 combined. LCD message: 'Memory 3 Settings Saved' + audible bong.";
